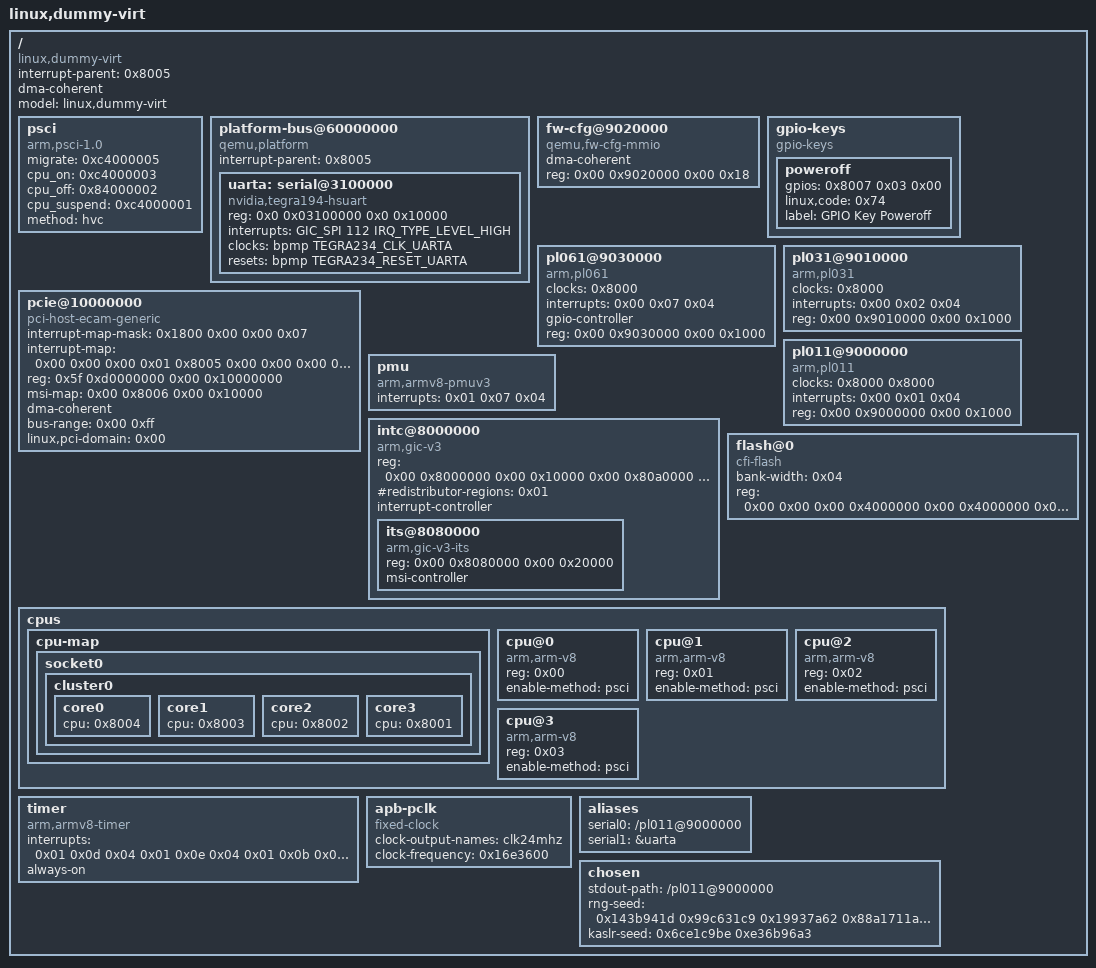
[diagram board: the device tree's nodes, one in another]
#include <dt-bindings/interrupt-controller/arm-gic.h>
#include <dt-bindings/clock/tegra234-clock.h>
#include <dt-bindings/reset/tegra234-reset.h>

/dts-v1/;

/ {
	interrupt-parent = <0x8005>;
	dma-coherent;
	model = "linux,dummy-virt";
	#size-cells = <0x02>;
	#address-cells = <0x02>;
	compatible = "linux,dummy-virt";

	psci {
		migrate = <0xc4000005>;
		cpu_on = <0xc4000003>;
		cpu_off = <0x84000002>;
		cpu_suspend = <0xc4000001>;
		method = "hvc";
		compatible = "arm,psci-1.0\0arm,psci-0.2\0arm,psci";
	};

	platform-bus@60000000 {
		interrupt-parent = <0x8005>;
		ranges = <0x00 0x03100000 0x00 0x60000000 0x00 0x10000>;
		#address-cells = <0x02>;
		#size-cells = <0x02>;
		compatible = "qemu,platform\0simple-bus";

		uarta: serial@3100000 {
			/* compatible = "nvidia,tegra234-uart", "nvidia,tegra20-uart" */
			reg = <0x0 0x03100000 0x0 0x10000>;
			interrupts = <GIC_SPI 112 IRQ_TYPE_LEVEL_HIGH>;
			clocks = <&bpmp TEGRA234_CLK_UARTA>;
			resets = <&bpmp TEGRA234_RESET_UARTA>;
			/* status = "disabled"; */
			compatible = "nvidia,tegra194-hsuart";
			reset-names = "serial";
			status = "okay";
		};
	};

	fw-cfg@9020000 {
		dma-coherent;
		reg = <0x00 0x9020000 0x00 0x18>;
		compatible = "qemu,fw-cfg-mmio";
	};

	gpio-keys {
		compatible = "gpio-keys";

		poweroff {
			gpios = <0x8007 0x03 0x00>;
			linux,code = <0x74>;
			label = "GPIO Key Poweroff";
		};
	};

	pl061@9030000 {
		phandle = <0x8007>;
		clock-names = "apb_pclk";
		clocks = <0x8000>;
		interrupts = <0x00 0x07 0x04>;
		gpio-controller;
		#gpio-cells = <0x02>;
		compatible = "arm,pl061\0arm,primecell";
		reg = <0x00 0x9030000 0x00 0x1000>;
	};

	pcie@10000000 {
		interrupt-map-mask = <0x1800 0x00 0x00 0x07>;
		interrupt-map = <0x00 0x00 0x00 0x01 0x8005 0x00 0x00 0x00 0x03 0x04 0x00 0x00 0x00 0x02 0x8005 0x00 0x00 0x00 0x04 0x04 0x00 0x00 0x00 0x03 0x8005 0x00 0x00 0x00 0x05 0x04 0x00 0x00 0x00 0x04 0x8005 0x00 0x00 0x00 0x06 0x04 0x800 0x00 0x00 0x01 0x8005 0x00 0x00 0x00 0x04 0x04 0x800 0x00 0x00 0x02 0x8005 0x00 0x00 0x00 0x05 0x04 0x800 0x00 0x00 0x03 0x8005 0x00 0x00 0x00 0x06 0x04 0x800 0x00 0x00 0x04 0x8005 0x00 0x00 0x00 0x03 0x04 0x1000 0x00 0x00 0x01 0x8005 0x00 0x00 0x00 0x05 0x04 0x1000 0x00 0x00 0x02 0x8005 0x00 0x00 0x00 0x06 0x04 0x1000 0x00 0x00 0x03 0x8005 0x00 0x00 0x00 0x03 0x04 0x1000 0x00 0x00 0x04 0x8005 0x00 0x00 0x00 0x04 0x04 0x1800 0x00 0x00 0x01 0x8005 0x00 0x00 0x00 0x06 0x04 0x1800 0x00 0x00 0x02 0x8005 0x00 0x00 0x00 0x03 0x04 0x1800 0x00 0x00 0x03 0x8005 0x00 0x00 0x00 0x04 0x04 0x1800 0x00 0x00 0x04 0x8005 0x00 0x00 0x00 0x05 0x04>;
		#interrupt-cells = <0x01>;
		ranges = <0x1000000 0x00 0x00 0x00 0x3eff0000 0x00 0x10000 0x2000000 0x00 0x10000000 0x00 0x10000000 0x00 0x2eff0000 0x3000000 0x80 0x00 0x80 0x00 0x80 0x00>;
		reg = <0x5f 0xd0000000 0x00 0x10000000>;
		msi-map = <0x00 0x8006 0x00 0x10000>;
		dma-coherent;
		bus-range = <0x00 0xff>;
		linux,pci-domain = <0x00>;
		#size-cells = <0x02>;
		#address-cells = <0x03>;
		device_type = "pci";
		compatible = "pci-host-ecam-generic";
	};

	pl031@9010000 {
		clock-names = "apb_pclk";
		clocks = <0x8000>;
		interrupts = <0x00 0x02 0x04>;
		reg = <0x00 0x9010000 0x00 0x1000>;
		compatible = "arm,pl031\0arm,primecell";
	};

	pl011@9000000 {
		clock-names = "uartclk\0apb_pclk";
		clocks = <0x8000 0x8000>;
		interrupts = <0x00 0x01 0x04>;
		reg = <0x00 0x9000000 0x00 0x1000>;
		compatible = "arm,pl011\0arm,primecell";
	};

	pmu {
		interrupts = <0x01 0x07 0x04>;
		compatible = "arm,armv8-pmuv3";
	};

	intc@8000000 {
		phandle = <0x8005>;
		reg = <0x00 0x8000000 0x00 0x10000 0x00 0x80a0000 0x00 0xf60000>;
		#redistributor-regions = <0x01>;
		compatible = "arm,gic-v3";
		ranges;
		#size-cells = <0x02>;
		#address-cells = <0x02>;
		interrupt-controller;
		#interrupt-cells = <0x03>;

		its@8080000 {
			phandle = <0x8006>;
			reg = <0x00 0x8080000 0x00 0x20000>;
			#msi-cells = <0x01>;
			msi-controller;
			compatible = "arm,gic-v3-its";
		};
	};

	flash@0 {
		bank-width = <0x04>;
		reg = <0x00 0x00 0x00 0x4000000 0x00 0x4000000 0x00 0x4000000>;
		compatible = "cfi-flash";
	};

	cpus {
		#size-cells = <0x00>;
		#address-cells = <0x01>;

		cpu-map {

			socket0 {

				cluster0 {

					core0 {
						cpu = <0x8004>;
					};

					core1 {
						cpu = <0x8003>;
					};

					core2 {
						cpu = <0x8002>;
					};

					core3 {
						cpu = <0x8001>;
					};
				};
			};
		};

		cpu@0 {
			phandle = <0x8004>;
			reg = <0x00>;
			enable-method = "psci";
			compatible = "arm,arm-v8";
			device_type = "cpu";
		};

		cpu@1 {
			phandle = <0x8003>;
			reg = <0x01>;
			enable-method = "psci";
			compatible = "arm,arm-v8";
			device_type = "cpu";
		};

		cpu@2 {
			phandle = <0x8002>;
			reg = <0x02>;
			enable-method = "psci";
			compatible = "arm,arm-v8";
			device_type = "cpu";
		};

		cpu@3 {
			phandle = <0x8001>;
			reg = <0x03>;
			enable-method = "psci";
			compatible = "arm,arm-v8";
			device_type = "cpu";
		};
	};

	timer {
		interrupts = <0x01 0x0d 0x04 0x01 0x0e 0x04 0x01 0x0b 0x04 0x01 0x0a 0x04>;
		always-on;
		compatible = "arm,armv8-timer\0arm,armv7-timer";
	};

	apb-pclk {
		phandle = <0x8000>;
		clock-output-names = "clk24mhz";
		clock-frequency = <0x16e3600>;
		#clock-cells = <0x00>;
		compatible = "fixed-clock";
	};

	aliases {
		serial0 = "/pl011@9000000";
		serial1 = &uarta;
	};

	chosen {
		stdout-path = "/pl011@9000000";
		rng-seed = <0x143b941d 0x99c631c9 0x19937a62 0x88a1711a 0x3ef7e86f 0xf3062f37 0x58040701 0x1ca6308>;
		kaslr-seed = <0x6ce1c9be 0xe36b96a3>;
	};
};
